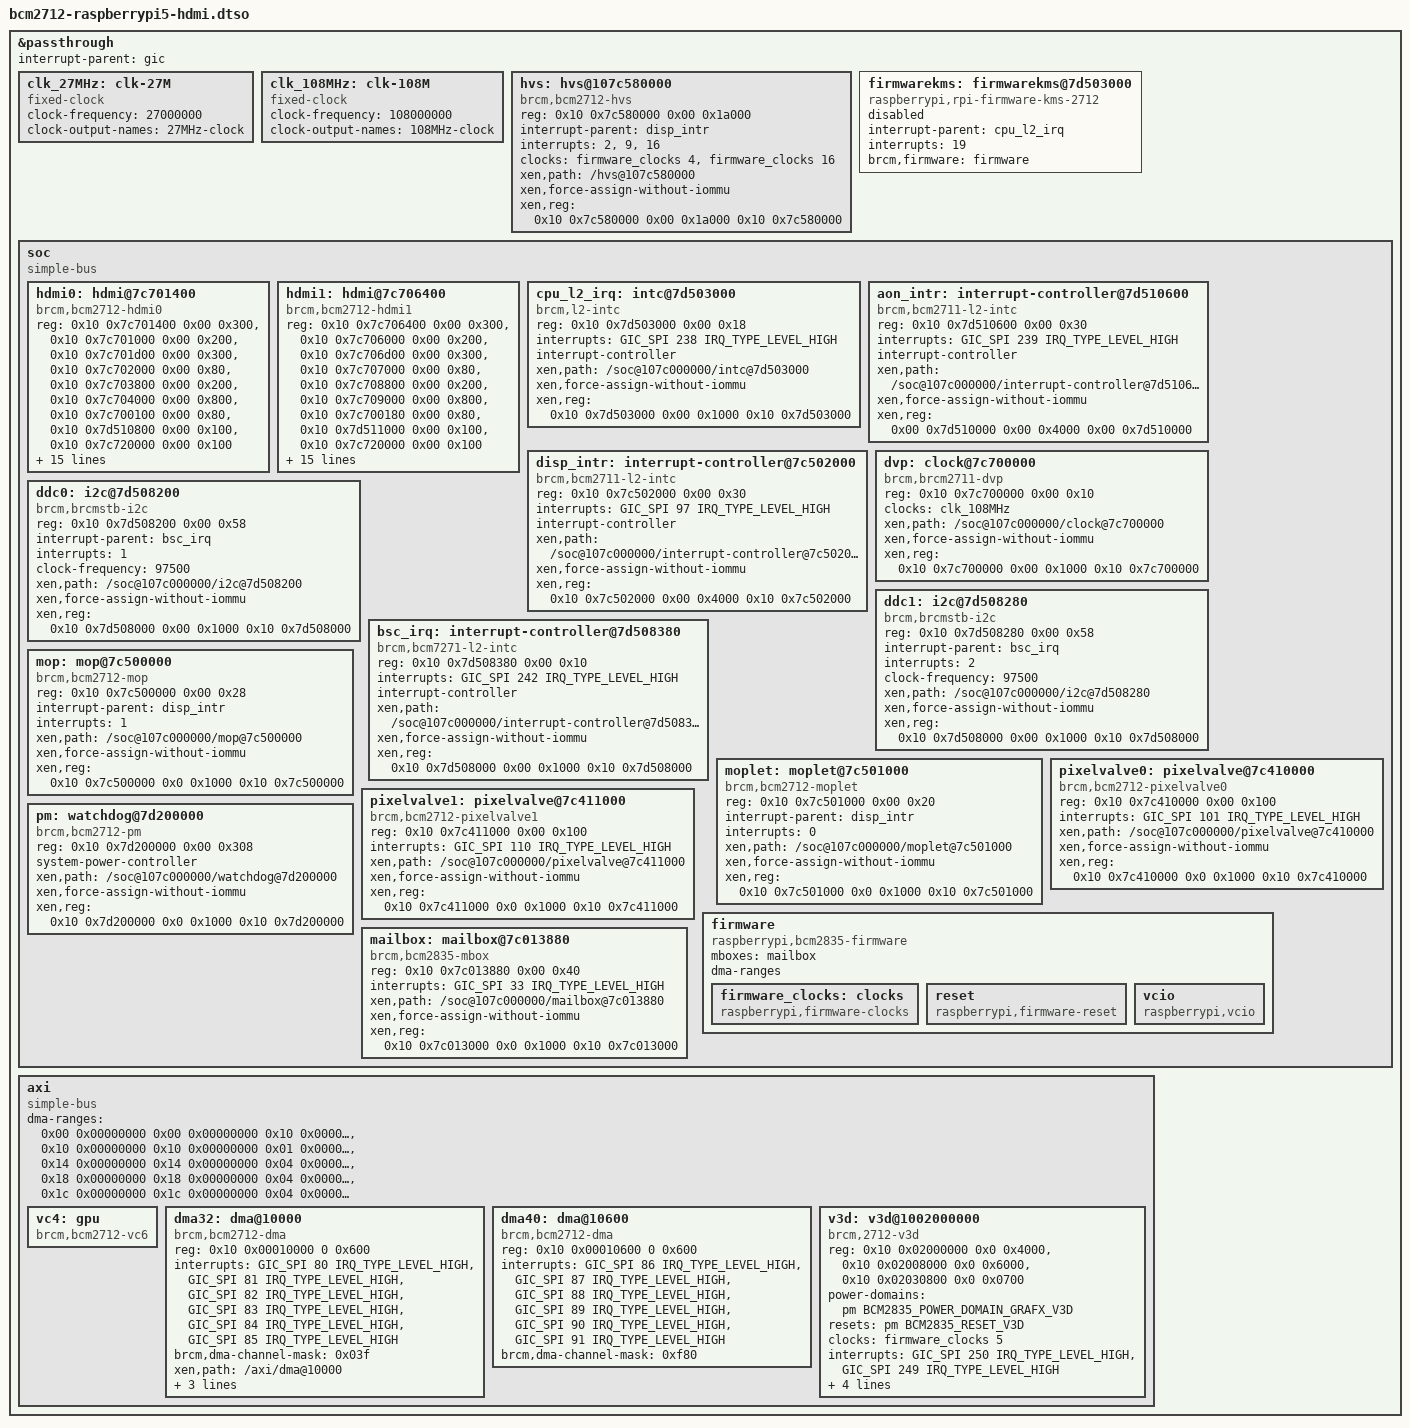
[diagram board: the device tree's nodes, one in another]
/*
 * Copyright (c) 2025 EPAM systems
 *
 * SPDX-License-Identifier: Apache-2.0
*/
/dts-v1/;
/plugin/;

#include <dt-bindings/clock/rp1.h>
#include <dt-bindings/interrupt-controller/arm-gic.h>
#include <dt-bindings/soc/bcm2835-pm.h>
#include <dt-bindings/mfd/rp1.h>

&passthrough {
	interrupt-parent = <&gic>;

	clk_27MHz: clk-27M {
		#clock-cells = <0>;
		compatible = "fixed-clock";
		clock-frequency = <27000000>;
		clock-output-names = "27MHz-clock";
	};

	clk_108MHz: clk-108M {
		#clock-cells = <0>;
		compatible = "fixed-clock";
		clock-frequency = <108000000>;
		clock-output-names = "108MHz-clock";
	};

	hvs: hvs@107c580000 {
		compatible = "brcm,bcm2712-hvs";
		reg = <0x10 0x7c580000 0x00 0x1a000>;
		interrupt-parent = <&disp_intr>;
		interrupts = <2>, <9>, <16>;
		interrupt-names = "ch0-eof", "ch1-eof", "ch2-eof";
		clocks = <&firmware_clocks 4>, <&firmware_clocks 16>;
		clock-names = "core", "disp";
		xen,path = "/hvs@107c580000";
		xen,force-assign-without-iommu;
		xen,reg = <0x10 0x7c580000 0x00 0x1a000 0x10 0x7c580000>;
		status= "okay";
	};

	firmwarekms: firmwarekms@7d503000 {
		compatible = "raspberrypi,rpi-firmware-kms-2712";
		interrupt-parent = <&cpu_l2_irq>;
		interrupts = <19>;
		brcm,firmware = <&firmware>;
		status = "disabled";
	};

	soc: soc {
		compatible = "simple-bus";
		#address-cells = <2>;
		#size-cells = <2>;
		ranges;

		hdmi0: hdmi@7c701400 {
			compatible = "brcm,bcm2712-hdmi0";
			reg = <0x10 0x7c701400 0x00 0x300>,
			      <0x10 0x7c701000 0x00 0x200>,
			      <0x10 0x7c701d00 0x00 0x300>,
			      <0x10 0x7c702000 0x00 0x80>,
			      <0x10 0x7c703800 0x00 0x200>,
			      <0x10 0x7c704000 0x00 0x800>,
			      <0x10 0x7c700100 0x00 0x80>,
			      <0x10 0x7d510800 0x00 0x100>,
			      <0x10 0x7c720000 0x00 0x100>;
			reg-names = "hdmi",
				    "dvp",
				    "phy",
				    "rm",
				    "packet",
				    "metadata",
				    "csc",
				    "cec",
				    "hd";
			resets = <&dvp 1>;
			interrupt-parent = <&aon_intr>;
			interrupts = <1>, <2>, <3>,
				     <7>, <8>;
			interrupt-names = "cec-tx", "cec-rx", "cec-low",
					  "hpd-connected", "hpd-removed";
			ddc = <&ddc0>;
			dmas = <&dma40 (10|(1<<30)|(1<<24)|(10<<16)|(15<<20))>;
			dma-names = "audio-rx";
			clocks = <&firmware_clocks 13>, <&firmware_clocks 14>, <&dvp 0>, <&clk_27MHz>;
			clock-names = "hdmi", "bvb", "audio", "cec";
			xen,path = "/soc@107c000000/hdmi@7c701400";
			xen,force-assign-without-iommu;
			xen,reg = <0x10 0x7c700000 0x00 0x1000 0x10 0x7c700000>,
				  <0x10 0x7c701000 0x00 0x4000 0x10 0x7c701000>,
				  <0x10 0x7c720000 0x00 0x1000 0x10 0x7c720000>,
				  <0x10 0x7d510000 0x00 0x1000 0x10 0x7d510000>;
			status = "okay";
		};

		hdmi1: hdmi@7c706400 {
			compatible = "brcm,bcm2712-hdmi1";
			reg = <0x10 0x7c706400 0x00 0x300>,
			      <0x10 0x7c706000 0x00 0x200>,
			      <0x10 0x7c706d00 0x00 0x300>,
			      <0x10 0x7c707000 0x00 0x80>,
			      <0x10 0x7c708800 0x00 0x200>,
			      <0x10 0x7c709000 0x00 0x800>,
			      <0x10 0x7c700180 0x00 0x80>,
			      <0x10 0x7d511000 0x00 0x100>,
			      <0x10 0x7c720000 0x00 0x100>;
			reg-names = "hdmi",
				    "dvp",
				    "phy",
				    "rm",
				    "packet",
				    "metadata",
				    "csc",
				    "cec",
				    "hd";
			ddc = <&ddc1>;
			resets = <&dvp 2>;
			interrupt-parent = <&aon_intr>;
			interrupts = <11>, <12>, <13>,
				     <14>, <15>;
			interrupt-names = "cec-tx", "cec-rx", "cec-low",
					  "hpd-connected", "hpd-removed";
			dmas = <&dma40 (17|(1<<30)|(1<<24)|(10<<16)|(15<<20))>;
			dma-names = "audio-rx";
			clocks = <&firmware_clocks 13>, <&firmware_clocks 14>, <&dvp 1>, <&clk_27MHz>;
			clock-names = "hdmi", "bvb", "audio", "cec";
			xen,path = "/soc@107c000000/hdmi@7c706400";
			xen,force-assign-without-iommu;
			xen,reg = <0x10 0x7c700000 0x00 0x1000 0x10 0x7c700000>,
				  <0x10 0x7c706000 0x00 0x4000 0x10 0x7c706000>,
				  <0x10 0x7c720000 0x00 0x1000 0x10 0x7c720000>,
				  <0x10 0x7d511000 0x00 0x1000 0x10 0x7d511000>;
			status = "okay";
		};

		cpu_l2_irq: intc@7d503000 {
			compatible = "brcm,l2-intc";
			reg = <0x10 0x7d503000 0x00 0x18>;
			interrupts = <GIC_SPI 238 IRQ_TYPE_LEVEL_HIGH>;
			interrupt-controller;
			#interrupt-cells = <1>;
			xen,path = "/soc@107c000000/intc@7d503000";
			xen,force-assign-without-iommu;
			xen,reg = <0x10 0x7d503000 0x00 0x1000 0x10 0x7d503000>;
		};

		aon_intr: interrupt-controller@7d510600 {
			compatible = "brcm,bcm2711-l2-intc", "brcm,l2-intc";
			reg = <0x10 0x7d510600 0x00 0x30>;
			interrupts = <GIC_SPI 239 IRQ_TYPE_LEVEL_HIGH>;
			interrupt-controller;
			#interrupt-cells = <1>;
			xen,path = "/soc@107c000000/interrupt-controller@7d510600";
			xen,force-assign-without-iommu;
			xen,reg = <0x00 0x7d510000 0x00 0x4000 0x00 0x7d510000>;
			status = "okay";
		};

		disp_intr: interrupt-controller@7c502000 {
			compatible = "brcm,bcm2711-l2-intc", "brcm,l2-intc";
			reg = <0x10 0x7c502000 0x00 0x30>;
			interrupts = <GIC_SPI 97 IRQ_TYPE_LEVEL_HIGH>;
			interrupt-controller;
			#interrupt-cells = <1>;
			xen,path = "/soc@107c000000/interrupt-controller@7c502000";
			xen,force-assign-without-iommu;
			xen,reg = <0x10 0x7c502000 0x00 0x4000 0x10 0x7c502000>;
			status = "okay";
		};

		dvp: clock@7c700000 {
			compatible = "brcm,brcm2711-dvp";
			reg = <0x10 0x7c700000 0x00 0x10>;
			clocks = <&clk_108MHz>;
			#clock-cells = <1>;
			#reset-cells = <1>;
			xen,path = "/soc@107c000000/clock@7c700000";
			xen,force-assign-without-iommu;
			xen,reg = <0x10 0x7c700000 0x00 0x1000 0x10 0x7c700000>;
		};

		ddc0: i2c@7d508200 {
			compatible = "brcm,brcmstb-i2c";
			reg = <0x10 0x7d508200 0x00 0x58>;
			interrupt-parent = <&bsc_irq>;
			interrupts = <1>;
			clock-frequency = <97500>;
			#address-cells = <1>;
			#size-cells = <0>;
			xen,path = "/soc@107c000000/i2c@7d508200";
			xen,force-assign-without-iommu;
			xen,reg = <0x10 0x7d508000 0x00 0x1000 0x10 0x7d508000>;
			status = "okay";
		};

		ddc1: i2c@7d508280 {
			compatible = "brcm,brcmstb-i2c";
			reg = <0x10 0x7d508280 0x00 0x58>;
			interrupt-parent = <&bsc_irq>;
			interrupts = <2>;
			clock-frequency = <97500>;
			#address-cells = <1>;
			#size-cells = <0>;
			xen,path = "/soc@107c000000/i2c@7d508280";
			xen,force-assign-without-iommu;
			xen,reg = <0x10 0x7d508000 0x00 0x1000 0x10 0x7d508000>;
			status = "okay";
		};

		bsc_irq: interrupt-controller@7d508380 {
			compatible = "brcm,bcm7271-l2-intc";
			reg = <0x10 0x7d508380 0x00 0x10>;
			interrupts = <GIC_SPI 242 IRQ_TYPE_LEVEL_HIGH>;
			interrupt-controller;
			#interrupt-cells = <1>;
			xen,path = "/soc@107c000000/interrupt-controller@7d508380";
			xen,force-assign-without-iommu;
			xen,reg = <0x10 0x7d508000 0x00 0x1000 0x10 0x7d508000>;
		};

		mop: mop@7c500000 {
			compatible = "brcm,bcm2712-mop";
			reg = <0x10 0x7c500000 0x00 0x28>;
			interrupt-parent = <&disp_intr>;
			interrupts = <1>;
			xen,path = "/soc@107c000000/mop@7c500000";
			xen,force-assign-without-iommu;
			xen,reg = <0x10 0x7c500000 0x0 0x1000 0x10 0x7c500000>;
			status = "okay";
		};

		moplet: moplet@7c501000 {
			compatible = "brcm,bcm2712-moplet";
			reg = <0x10 0x7c501000 0x00 0x20>;
			interrupt-parent = <&disp_intr>;
			interrupts = <0>;
			xen,path = "/soc@107c000000/moplet@7c501000";
			xen,force-assign-without-iommu;
			xen,reg = <0x10 0x7c501000 0x0 0x1000 0x10 0x7c501000>;
			status = "okay";
		};

		pixelvalve0: pixelvalve@7c410000 {
			compatible = "brcm,bcm2712-pixelvalve0";
			reg = <0x10 0x7c410000 0x00 0x100>;
			interrupts = <GIC_SPI 101 IRQ_TYPE_LEVEL_HIGH>;
			xen,path = "/soc@107c000000/pixelvalve@7c410000";
			xen,force-assign-without-iommu;
			xen,reg = <0x10 0x7c410000 0x0 0x1000 0x10 0x7c410000>;
			status = "okay";
		};

		pixelvalve1: pixelvalve@7c411000 {
			compatible = "brcm,bcm2712-pixelvalve1";
			reg = <0x10 0x7c411000 0x00 0x100>;
			interrupts = <GIC_SPI 110 IRQ_TYPE_LEVEL_HIGH>;
			xen,path = "/soc@107c000000/pixelvalve@7c411000";
			xen,force-assign-without-iommu;
			xen,reg = <0x10 0x7c411000 0x0 0x1000 0x10 0x7c411000>;
			status = "okay";
		};

		pm: watchdog@7d200000 {
			compatible = "brcm,bcm2712-pm";
			reg = <0x10 0x7d200000 0x00 0x308>;
			reg-names = "pm";
			#power-domain-cells = <1>;
			#reset-cells = <1>;
			system-power-controller;
			xen,path = "/soc@107c000000/watchdog@7d200000";
			xen,force-assign-without-iommu;
			xen,reg = <0x10 0x7d200000 0x0 0x1000 0x10 0x7d200000>;
		};

		firmware: firmware {
			compatible = "raspberrypi,bcm2835-firmware", "simple-mfd";
			#address-cells = <1>;
			#size-cells = <1>;

			mboxes = <&mailbox>;
			dma-ranges;

			firmware_clocks: clocks {
				compatible = "raspberrypi,firmware-clocks";
				#clock-cells = <1>;
			};

			reset: reset {
				compatible = "raspberrypi,firmware-reset";
				#reset-cells = <1>;
			};

			vcio: vcio {
				compatible = "raspberrypi,vcio";
			};
		};

		mailbox: mailbox@7c013880 {
			compatible = "brcm,bcm2835-mbox";
			reg = <0x10 0x7c013880 0x00 0x40>;
			interrupts = <GIC_SPI 33 IRQ_TYPE_LEVEL_HIGH>;
			#mbox-cells = <0>;
			xen,path = "/soc@107c000000/mailbox@7c013880";
			xen,force-assign-without-iommu;
			xen,reg = <0x10 0x7c013000 0x0 0x1000 0x10 0x7c013000>;
			status = "okay";
		};
	};

	axi: axi {
		compatible = "simple-bus";
		#address-cells = <2>;
		#size-cells = <2>;
		ranges = <0x00 0x00000000 0x00 0x00000000 0x10 0x00000000>,
			 <0x10 0x00000000 0x10 0x00000000 0x01 0x00000000>,
			 <0x14 0x00000000 0x14 0x00000000 0x04 0x00000000>,
			 <0x18 0x00000000 0x18 0x00000000 0x04 0x00000000>,
			 <0x1c 0x00000000 0x1c 0x00000000 0x04 0x00000000>;

		dma-ranges = <0x00 0x00000000 0x00 0x00000000 0x10 0x00000000>,
			     <0x10 0x00000000 0x10 0x00000000 0x01 0x00000000>,
			     <0x14 0x00000000 0x14 0x00000000 0x04 0x00000000>,
			     <0x18 0x00000000 0x18 0x00000000 0x04 0x00000000>,
			     <0x1c 0x00000000 0x1c 0x00000000 0x04 0x00000000>;

		vc4: gpu {
			compatible = "brcm,bcm2712-vc6";
			status = "okay";
		};

		dma32: dma@10000 {
			compatible = "brcm,bcm2712-dma";
			reg = <0x10 0x00010000 0 0x600>;
			interrupts = <GIC_SPI 80 IRQ_TYPE_LEVEL_HIGH>,
				     <GIC_SPI 81 IRQ_TYPE_LEVEL_HIGH>,
				     <GIC_SPI 82 IRQ_TYPE_LEVEL_HIGH>,
				     <GIC_SPI 83 IRQ_TYPE_LEVEL_HIGH>,
				     <GIC_SPI 84 IRQ_TYPE_LEVEL_HIGH>,
				     <GIC_SPI 85 IRQ_TYPE_LEVEL_HIGH>;
			interrupt-names = "dma0",
					  "dma1",
					  "dma2",
					  "dma3",
					  "dma4",
					  "dma5";
			#dma-cells = <1>;
			brcm,dma-channel-mask = <0x03f>;
			xen,path = "/axi/dma@10000";
			xen,force-assign-without-iommu;
			xen,reg = <0x10 0x00010000 0x00 0x1000 0x10 0x00010000>;
		};


		dma40: dma@10600 {
			compatible = "brcm,bcm2712-dma";
			reg = <0x10 0x00010600 0 0x600>;
			interrupts =
				<GIC_SPI 86 IRQ_TYPE_LEVEL_HIGH>, /* dma4 6 */
				<GIC_SPI 87 IRQ_TYPE_LEVEL_HIGH>, /* dma4 7 */
				<GIC_SPI 88 IRQ_TYPE_LEVEL_HIGH>, /* dma4 8 */
				<GIC_SPI 89 IRQ_TYPE_LEVEL_HIGH>, /* dma4 9 */
				<GIC_SPI 90 IRQ_TYPE_LEVEL_HIGH>, /* dma4 10 */
				<GIC_SPI 91 IRQ_TYPE_LEVEL_HIGH>; /* dma4 11 */
			interrupt-names = "dma6",
					  "dma7",
					  "dma8",
					  "dma9",
					  "dma10",
					  "dma11";
			#dma-cells = <1>;
			brcm,dma-channel-mask = <0xf80>;
		};

		v3d: v3d@1002000000 {
			compatible = "brcm,2712-v3d";
			reg = <0x10 0x02000000  0x0 0x4000>,
			      <0x10 0x02008000  0x0 0x6000>,
			      <0x10 0x02030800  0x0 0x0700>;
			reg-names = "hub", "core0", "sms";

			power-domains = <&pm BCM2835_POWER_DOMAIN_GRAFX_V3D>;
			resets = <&pm BCM2835_RESET_V3D>;
			clocks = <&firmware_clocks 5>;
			clock-names = "v3d";
			interrupts = <GIC_SPI 250 IRQ_TYPE_LEVEL_HIGH>,
				     <GIC_SPI 249 IRQ_TYPE_LEVEL_HIGH>;
			xen,path = "/axi/v3d@2000000";
			xen,force-assign-without-iommu;
			xen,reg = <0x10 0x02000000 0x0 0x4000 0x10 0x02000000
				   0x10 0x02008000 0x0 0x6000 0x10 0x02008000
				   0x10 0x02030000 0x0 0x1000 0x10 0x02030000>;
			status = "okay";
		};
	};
};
